# ATSAMC21N18A register map
Vendor: Atmel Corporation; Series: SAMC21; File version: A
CPU: CM0+ r0p1, little endian, MPU, no FPU, VTOR, 2 interrupt priority bits
Registers are 32-bit, read-write, reset 0x0 unless marked. A register's access mark holds for its fields unless they carry their own. Offsets are from the block's base; [hi:lo] are bit positions; {n}, {i} and the like mark numbered series; 'fields as' and 'values as' point back to an identical list.

## SUPC — Supply Controller
Base 0x40001800; register names take the prefix SUPC_
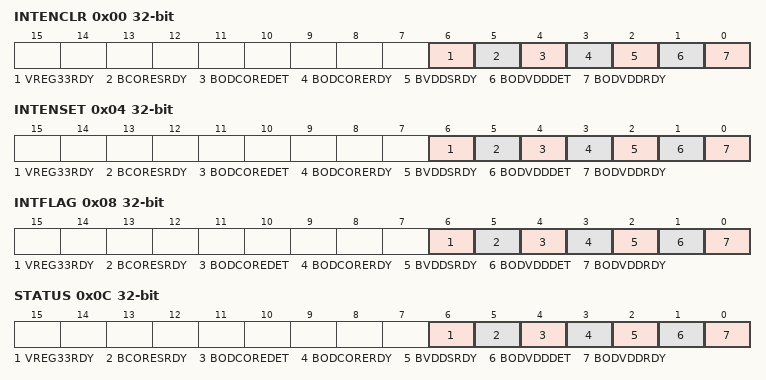
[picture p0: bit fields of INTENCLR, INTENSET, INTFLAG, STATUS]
0x00 INTENCLR — Interrupt Enable Clear
  [6] VREG33RDY — VREG33 Ready
  [5] BCORESRDY — BODCORE Synchronization Ready
  [4] BODCOREDET — BODCORE Detection
  [3] BODCORERDY — BODCORE Ready
  [2] BVDDSRDY — BODVDD Synchronization Ready
  [1] BODVDDDET — BODVDD Detection
  [0] BODVDDRDY — BODVDD Ready
0x04 INTENSET — Interrupt Enable Set
  fields as INTENCLR
0x08 INTFLAG — Interrupt Flag Status and Clear
  fields as INTENCLR
0x0C STATUS ro — Power and Clocks Status
  fields as INTENCLR
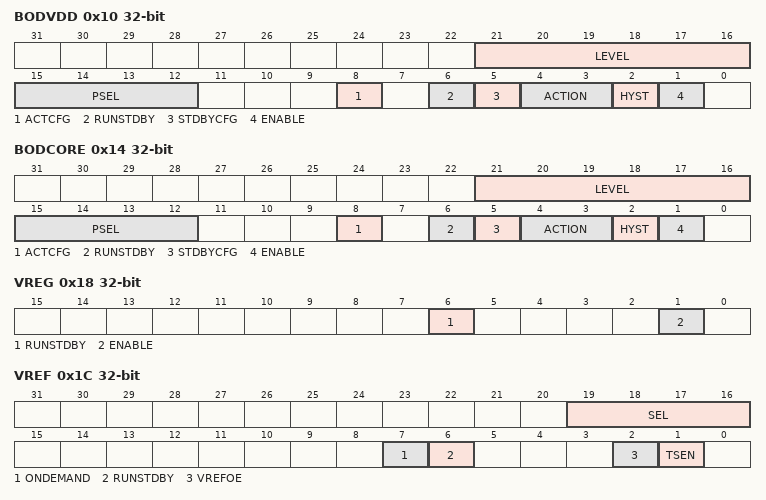
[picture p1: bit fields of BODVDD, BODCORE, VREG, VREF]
0x10 BODVDD — BODVDD Control
  [21:16] LEVEL — Threshold Level for VDD
  [15:12] PSEL — Prescaler Select
    0=DIV2 (Divide clock by 2); 1=DIV4 (Divide clock by 4); 2=DIV8 (Divide clock by 8); 3=DIV16 (Divide clock by 16); 4=DIV32 (Divide clock by 32); 5=DIV64 (Divide clock by 64); 6=DIV128 (Divide clock by 128); 7=DIV256 (Divide clock by 256); 8=DIV512 (Divide clock by 512); 9=DIV1024 (Divide clock by 1024); 10=DIV2048 (Divide clock by 2048); 11=DIV4096 (Divide clock by 4096); 12=DIV8192 (Divide clock by 8192); 13=DIV16384 (Divide clock by 16384); 14=DIV32768 (Divide clock by 32768); 15=DIV65536 (Divide clock by 65536)
  [8] ACTCFG — Configuration in Active mode
  [6] RUNSTDBY — Run during Standby
  [5] STDBYCFG — Configuration in Standby mode
  [4:3] ACTION — Action when Threshold Crossed
    0=NONE (No action); 1=RESET (The BOD33 generates a reset); 2=INT (The BOD33 generates an interrupt)
  [2] HYST — Hysteresis Enable
  [1] ENABLE
0x14 BODCORE — BODCORE Control
  [21:16] LEVEL — Threshold Level
  [15:12] PSEL — Prescaler Select
    values as BODVDD.PSEL
  [8] ACTCFG — Configuration in Active mode
  [6] RUNSTDBY — Run during Standby
  [5] STDBYCFG — Configuration in Standby mode
  [4:3] ACTION — Action when Threshold Crossed
    0=NONE (No action); 1=RESET (The BOD12 generates a reset); 2=INT (The BOD12 generates an interrupt)
  [2] HYST — Hysteresis Enable
  [1] ENABLE
0x18 VREG — VREG Control
  [6] RUNSTDBY — Run during Standby
  [1] ENABLE
0x1C VREF — VREF Control
  [19:16] SEL — Voltage Reference Selection
    0=1V024 (1.024V voltage reference typical value); 2=2V048 (2.048V voltage reference typical value); 3=4V096 (4.096V voltage reference typical value)
  [7] ONDEMAND — On Demand Contrl
  [6] RUNSTDBY — Run during Standby
  [2] VREFOE — Voltage Reference Output Enable
  [1] TSEN — Temperature Sensor Output Enable
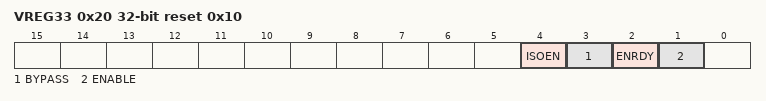
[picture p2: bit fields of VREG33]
0x20 VREG33 reset 0x10 — VREG33 Control
  [4] ISOEN — Isolation Enable
  [3] BYPASS — VREG33 Bypass
  [2] ENRDY — VREG33 Ready Enable
  [1] ENABLE — VREG33 Enable

## TAL — Trigger Allocator
Base 0x42006000; register names take the prefix TAL_
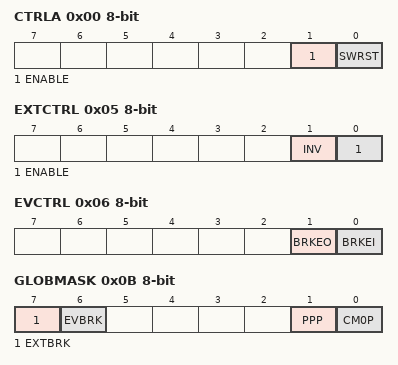
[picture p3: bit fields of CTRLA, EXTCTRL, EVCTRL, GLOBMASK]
0x00 CTRLA 8-bit — Control A
  [1] ENABLE
  [0] SWRST — Software Reset
0x04 RSTCTRL 8-bit — Reset Control
0x05 EXTCTRL 8-bit — External Break Control
  [1] INV — Invert BRK Pin
  [0] ENABLE — Enable BRK Pin
0x06 EVCTRL 8-bit — Event Control
  [1] BRKEO — Break Output Event Enable
  [0] BRKEI — Break Input Event Enable
0x08 INTENCLR 8-bit — Interrupt Enable Clear
  [0] BRK — Break Interrupt Enable
0x09 INTENSET 8-bit — Interrupt Enable Set
  [0] BRK — Break Interrupt Enable
0x0A INTFLAG 8-bit — Interrupt Flag Status and Clear
  [0] BRK — Break
0x0B GLOBMASK 8-bit — Global Break Requests Mask
  [7] EXTBRK — External Break Master
  [6] EVBRK — Event Break Master
  [1] PPP — PPP Break Master
  [0] CM0P — CM0P Break Master
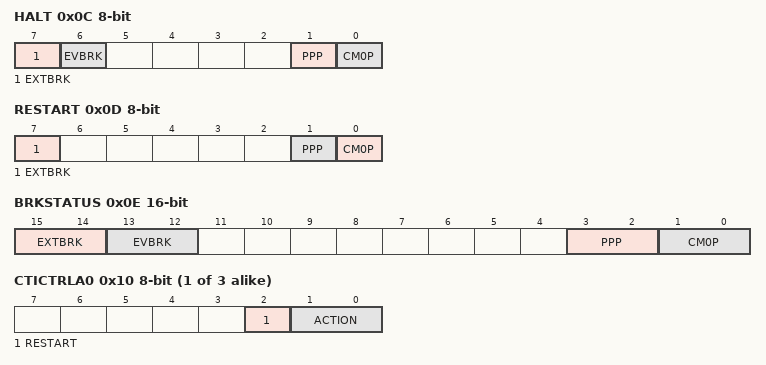
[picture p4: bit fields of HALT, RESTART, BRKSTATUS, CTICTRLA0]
0x0C HALT 8-bit wo — Debug Halt Request
  fields as GLOBMASK
0x0D RESTART 8-bit wo — Debug Restart Request
  [7] EXTBRK — External Break Master
  [1] PPP — PPP Break Master
  [0] CM0P — CM0P Break Master
0x0E BRKSTATUS 16-bit ro — Break Request Status
  [15:14] EXTBRK — External Break Request
    0=INT_RUN (External CPU running, by internal request); 1=INT_HALT (External CPU halted, by internal request); 2=EXT_RUN (External CPU running, by external request); 3=EXT_HALT (External CPU halted, by external request)
  [13:12] EVBRK — Event Break Request
    0=INT_RUN (EVBRK running)
  [3:2] PPP — PPP Break Request
    0=INT_RUN (PPP running, by internal request); 1=INT_HALT (PPP halted, by internal request); 2=EXT_RUN (PPP running, by external request); 3=EXT_HALT (PPP halted, by external request)
  [1:0] CM0P — CM0P Break Request
    0=INT_RUN (CM0P running, by internal request); 1=INT_HALT (CM0P halted, by internal request); 2=EXT_RUN (CM0P running, by external request); 3=EXT_HALT (CM0P halted, by external request)
{0x10+2i} CTICTRLA{i} (i=0..2) 8-bit — Cross-Trigger Interface n Control A
  [2] RESTART — Action when global restart issued
  [1:0] ACTION — Action when global break issued
    0=BREAK (Break when requested); 1=INTERRUPT (Trigger DBG interrupt instead of break); 2=IGNORE (Ignore break request)
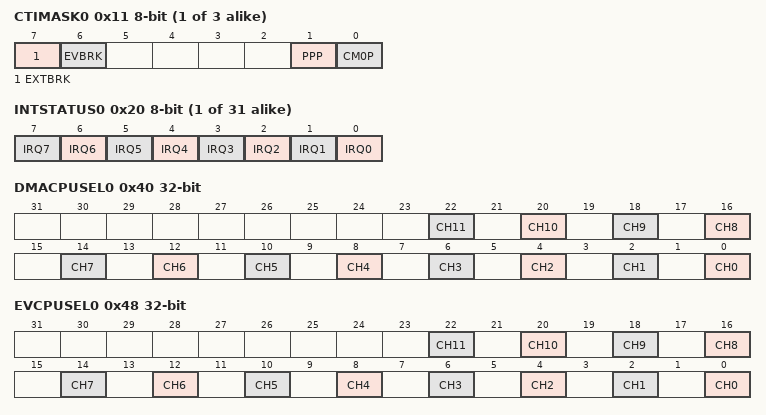
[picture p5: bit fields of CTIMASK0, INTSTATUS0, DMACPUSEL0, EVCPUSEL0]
{0x11+2i} CTIMASK{i} (i=0..2) 8-bit — Cross-Trigger Interface n Mask
  fields as GLOBMASK
{0x20+i} INTSTATUS{i} (i=0..30) 8-bit ro — Interrupt n Status
  [n] IRQ{n} (n=0..7) — Interrupt Status for Interrupt Request {n} within Interrupt n
0x40 DMACPUSEL0 — DMA Channel Interrupts CPU Select 0
  [2n] CH{n} (n=0..11) — DMA Channel {n} Interrupt CPU Select
0x48 EVCPUSEL0 — EVSYS Channel Interrupts CPU Select 0
  [2n] CH{n} (n=0..11) — Event Channel {n} Interrupt CPU Select
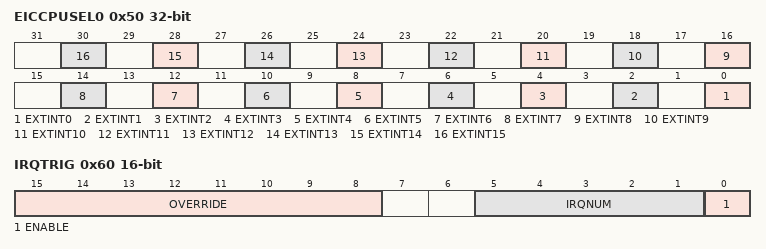
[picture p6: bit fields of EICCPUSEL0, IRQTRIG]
0x50 EICCPUSEL0 — EIC External Interrupts CPU Select 0
  [2n] EXTINT{n} (n=0..15) — External Interrupt {n} CPU Select
0x58 INTCPUSEL0 — Interrupts CPU Select 0
0x5C INTCPUSEL1 — Interrupts CPU Select 1
0x60 IRQTRIG 16-bit — Interrupt Trigger
  [15:8] OVERRIDE — Interrupt Request Override Value
  [5:1] IRQNUM — Interrupt Request Number
  [0] ENABLE — Trigger Enable

## TSENS — Temperature Sensor
Base 0x40003000; register names take the prefix TSENS_
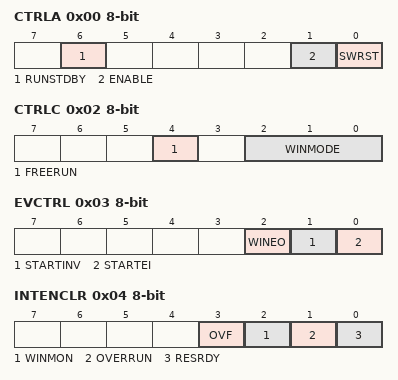
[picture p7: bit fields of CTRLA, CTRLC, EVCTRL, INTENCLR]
0x00 CTRLA 8-bit — Control A Register
  [6] RUNSTDBY — Run in Standby
  [1] ENABLE
  [0] SWRST — Software Reset
0x01 CTRLB 8-bit wo — Control B Register
  [0] START — Start Measurement
0x02 CTRLC 8-bit — Control C Register
  [4] FREERUN — Free Running Measurement
  [2:0] WINMODE — Window Monitor Mode
    0=DISABLE (No window mode (default)); 1=ABOVE (VALUE greater than WINLT); 2=BELOW (VALUE less than WINUT); 3=INSIDE (VALUE greater than WINLT and VALUE less than WINUT); 4=OUTSIDE (VALUE less than WINLT or VALUE greater than WINUT); 5=HYST_ABOVE (VALUE greater than WINUT with hysteresis to WINLT); 6=HYST_BELOW (VALUE less than WINLST with hysteresis to WINUT)
0x03 EVCTRL 8-bit — Event Control Register
  [2] WINEO — Window Monitor Event Out
  [1] STARTINV — Start Conversion Event Invert Enable
  [0] STARTEI — Start Conversion Event Input Enable
0x04 INTENCLR 8-bit — Interrupt Enable Clear Register
  [3] OVF — Overflow Interrupt Enable
  [2] WINMON — Window Monitor Interrupt Enable
  [1] OVERRUN — Overrun Interrupt Enable
  [0] RESRDY — Result Ready Interrupt Enable
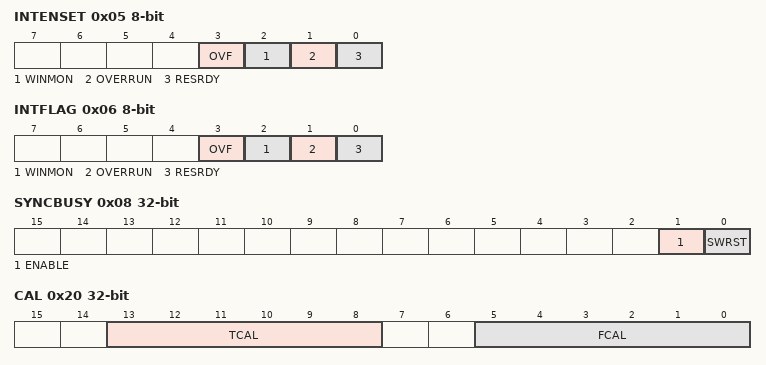
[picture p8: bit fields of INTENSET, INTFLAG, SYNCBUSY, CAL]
0x05 INTENSET 8-bit — Interrupt Enable Set Register
  fields as INTENCLR
0x06 INTFLAG 8-bit — Interrupt Flag Status and Clear Register
  [3] OVF — Overflow
  [2] WINMON — Window Monitor
  [1] OVERRUN
  [0] RESRDY — Result Ready
0x07 STATUS 8-bit ro
  [0] OVF — Result Overflow
0x08 SYNCBUSY ro — Synchronization Busy Register
  [1] ENABLE — Enable Busy
  [0] SWRST — Software Reset Busy
0x0C VALUE ro
  [23:0] VALUE — Measurement Value
0x10 WINLT — Window Monitor Lower Threshold Register
  [23:0] WINLT — Window Lower Threshold
0x14 WINUT — Window Monitor Upper Threshold Register
  [23:0] WINUT — Window Upper Threshold
0x18 GAIN
  [23:0] GAIN — Time Amplifier Gain
0x1C OFFSET
  [23:0] OFFSETC — Offset Correction
0x20 CAL — Calibration Register
  [13:8] TCAL — Temperature Calibration
  [5:0] FCAL — Frequency Calibration
0x24 DBGCTRL 8-bit — Debug Control Register
  [0] DBGRUN — Debug Run

## WDT — Watchdog Timer
Base 0x40002000; register names take the prefix WDT_
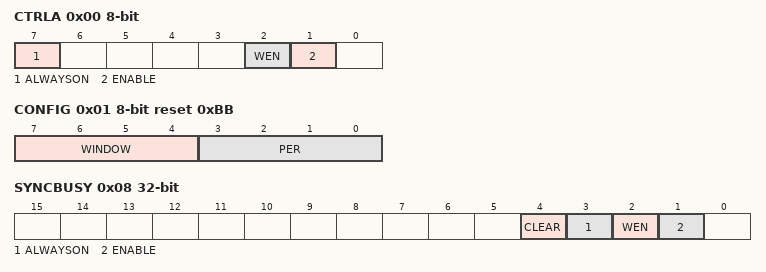
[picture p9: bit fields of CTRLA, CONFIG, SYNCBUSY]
0x00 CTRLA 8-bit — Control
  [7] ALWAYSON
  [2] WEN — Watchdog Timer Window Mode Enable
  [1] ENABLE
0x01 CONFIG 8-bit reset 0xBB — Configuration
  [7:4] WINDOW — Window Mode Time-Out Period
    0=CYC8 (8 clock cycles); 1=CYC16 (16 clock cycles); 2=CYC32 (32 clock cycles); 3=CYC64 (64 clock cycles); 4=CYC128 (128 clock cycles); 5=CYC256 (256 clock cycles); 6=CYC512 (512 clock cycles); 7=CYC1024 (1024 clock cycles); 8=CYC2048 (2048 clock cycles); 9=CYC4096 (4096 clock cycles); 10=CYC8192 (8192 clock cycles); 11=CYC16384 (16384 clock cycles)
  [3:0] PER — Time-Out Period
    values as WINDOW
0x02 EWCTRL 8-bit reset 0xB — Early Warning Interrupt Control
  [3:0] EWOFFSET — Early Warning Interrupt Time Offset
    values as CONFIG.WINDOW
0x04 INTENCLR 8-bit — Interrupt Enable Clear
  [0] EW — Early Warning Interrupt Enable
0x05 INTENSET 8-bit — Interrupt Enable Set
  [0] EW — Early Warning Interrupt Enable
0x06 INTFLAG 8-bit — Interrupt Flag Status and Clear
  [0] EW — Early Warning
0x08 SYNCBUSY ro — Synchronization Busy
  [4] CLEAR — Clear Busy
  [3] ALWAYSON — Always-On Busy
  [2] WEN — Window Enable Busy
  [1] ENABLE — Enable Busy
0x0C CLEAR 8-bit wo
  [7:0] CLEAR — Watchdog Clear
    165=KEY (Clear Key)
